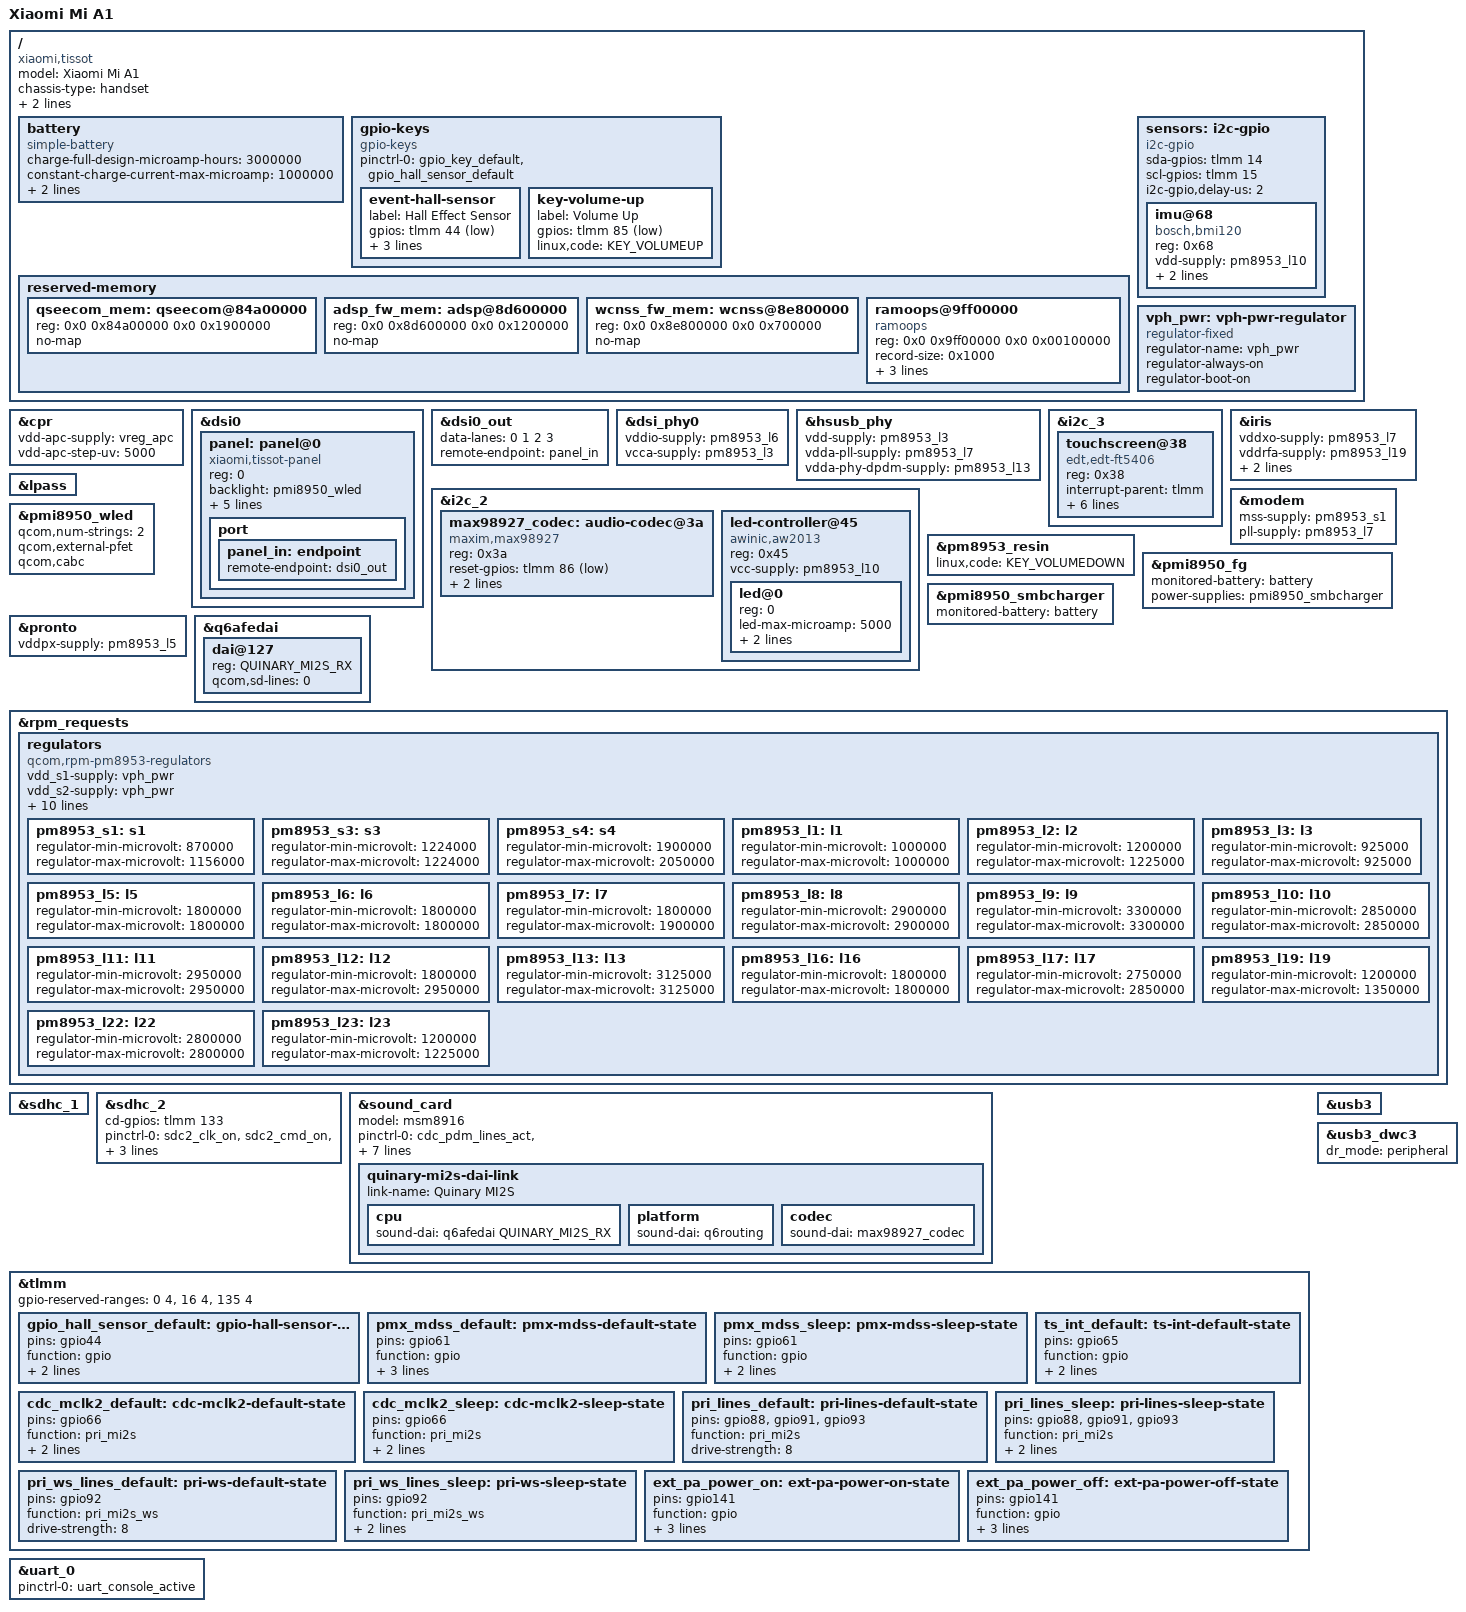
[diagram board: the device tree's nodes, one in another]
// SPDX-License-Identifier: BSD-3-Clause
/*
 * Copyright (c) 2022, Danila Tikhonov <JIaxyga@protonmail.com>
 * Copyright (c) 2022, Anton Bambura <jenneron@protonmail.com>
 */
/dts-v1/;

#include "msm8953.dtsi"
#include "pm8953.dtsi"
#include "pmi8950.dtsi"
#include <dt-bindings/leds/common.h>

/delete-node/ &adsp_fw_mem;
/delete-node/ &wcnss_fw_mem;

/ {
	model = "Xiaomi Mi A1";
	compatible = "xiaomi,tissot", "qcom,msm8953";
	chassis-type = "handset";
	qcom,msm-id = <293 0>;
	qcom,board-id = <0x1000b 0x00>;

	battery: battery {
		compatible = "simple-battery";
		charge-full-design-microamp-hours = <3000000>;
		constant-charge-current-max-microamp = <1000000>;
		voltage-min-design-microvolt = <3400000>;
		voltage-max-design-microvolt = <4400000>;
	};

	gpio-keys {
		compatible = "gpio-keys";

		pinctrl-names = "default";
		pinctrl-0 = <&gpio_key_default>, <&gpio_hall_sensor_default>;

		event-hall-sensor {
			label = "Hall Effect Sensor";
			gpios = <&tlmm 44 GPIO_ACTIVE_LOW>;
			linux,input-type = <EV_SW>;
			linux,code = <SW_LID>;
			linux,can-disable;
		};

		key-volume-up {
			label = "Volume Up";
			gpios = <&tlmm 85 GPIO_ACTIVE_LOW>;
			linux,code = <KEY_VOLUMEUP>;
		};
	};

	reserved-memory {
		/delete-node/memory@85b00000;
		qseecom_mem: qseecom@84a00000 {
			reg = <0x0 0x84a00000 0x0 0x1900000>;
			no-map;
		};

		adsp_fw_mem: adsp@8d600000 {
			reg = <0x0 0x8d600000 0x0 0x1200000>;
			no-map;
		};

		wcnss_fw_mem: wcnss@8e800000 {
			reg = <0x0 0x8e800000 0x0 0x700000>;
			no-map;
		};

		ramoops@9ff00000 {
			compatible = "ramoops";
			reg = <0x0 0x9ff00000 0x0 0x00100000>;
			record-size = <0x1000>;
			console-size = <0x80000>;
			ftrace-size = <0x1000>;
			pmsg-size = <0x8000>;
		};
	};

	sensors: i2c-gpio {
		compatible = "i2c-gpio";
		sda-gpios = <&tlmm 14 (GPIO_ACTIVE_HIGH|GPIO_OPEN_DRAIN)>;
		scl-gpios = <&tlmm 15 (GPIO_ACTIVE_HIGH|GPIO_OPEN_DRAIN)>;
		i2c-gpio,delay-us = <2>;        /* ~100 kHz */
		#address-cells = <1>;
		#size-cells = <0>;

		imu@68 {
			compatible = "bosch,bmi120";
			reg = <0x68>;

			vdd-supply = <&pm8953_l10>;
			vddio-supply = <&pm8953_l6>;

			mount-matrix = "0", "1", "0",
					"1", "0", "0",
					"0", "0", "1";
		};
	};

	vph_pwr: vph-pwr-regulator {
		compatible = "regulator-fixed";
		regulator-name = "vph_pwr";
		regulator-always-on;
		regulator-boot-on;
	};
};

&cpr {
	vdd-apc-supply = <&vreg_apc>;
	vdd-apc-step-uv = <5000>;
};

&dsi0 {
	panel: panel@0 {
		compatible = "xiaomi,tissot-panel";
		reg = <0>;

		backlight = <&pmi8950_wled>;

		reset-gpios = <&tlmm 61 GPIO_ACTIVE_LOW>;

		pinctrl-names = "default", "sleep";
		pinctrl-0 = <&pmx_mdss_default &mdss_te_default>;
		pinctrl-1 = <&pmx_mdss_sleep &mdss_te_default>;

		vsp-supply = <&lab_vreg>;
		vsn-supply = <&ibb_vreg>;

		port {
			panel_in: endpoint {
				remote-endpoint = <&dsi0_out>;
			};
		};
	};
};

&dsi0_out {
	data-lanes = <0 1 2 3>;
	remote-endpoint = <&panel_in>;
};

&dsi_phy0 {
	vddio-supply = <&pm8953_l6>;
	vcca-supply = <&pm8953_l3>;
};

&hsusb_phy {
	vdd-supply = <&pm8953_l3>;
	vdda-pll-supply = <&pm8953_l7>;
	vdda-phy-dpdm-supply = <&pm8953_l13>;

	status = "okay";
};

&i2c_2 {
	status = "okay";

	max98927_codec: audio-codec@3a {
		compatible = "maxim,max98927";
		reg = <0x3a>;

		reset-gpios = <&tlmm 86 GPIO_ACTIVE_LOW>;

		vmon-slot-no = <1>;
		imon-slot-no = <1>;

		#sound-dai-cells = <1>;
	};

	led-controller@45 {
		compatible = "awinic,aw2013";
		reg = <0x45>;

		vcc-supply = <&pm8953_l10>;

		#address-cells = <1>;
		#size-cells = <0>;

		led@0 {
			reg = <0>;
			led-max-microamp = <5000>;
			function = LED_FUNCTION_INDICATOR;
			color = <LED_COLOR_ID_WHITE>;
		};
	};
};

&i2c_3 {
	status = "okay";

	touchscreen@38 {
		compatible = "edt,edt-ft5406";
		reg = <0x38>;

		interrupt-parent = <&tlmm>;
		interrupts = <65 IRQ_TYPE_EDGE_FALLING>;

		pinctrl-names = "default";
		pinctrl-0 = <&ts_int_default>;

		reset-gpios = <&tlmm 64 GPIO_ACTIVE_LOW>;

		vcc-supply = <&pm8953_l10>;

		touchscreen-size-x = <1080>;
		touchscreen-size-y = <1920>;
	};
};

&iris {
	vddxo-supply = <&pm8953_l7>;
	vddrfa-supply = <&pm8953_l19>;
	vddpa-supply = <&pm8953_l9>;
	vdddig-supply = <&pm8953_l5>;

	status = "okay";
};

&lpass {
	status = "okay";
};

&modem {
	status = "okay";

	mss-supply = <&pm8953_s1>;
	pll-supply = <&pm8953_l7>;
};

&pm8953_resin {
	status = "okay";
	linux,code = <KEY_VOLUMEDOWN>;
};

&pmi8950_fg {
	monitored-battery = <&battery>;
	power-supplies = <&pmi8950_smbcharger>;
	status = "okay";
};

&pmi8950_smbcharger {
	monitored-battery = <&battery>;
	status = "okay";
};

&pmi8950_wled {
	status = "okay";

	qcom,num-strings = <2>;
	qcom,external-pfet;
	qcom,cabc;
};

&pronto {
	status = "okay";
	vddpx-supply = <&pm8953_l5>;
};

&q6afedai {
	dai@127 {
		reg = <QUINARY_MI2S_RX>;
		qcom,sd-lines = <0>;
	};
};

&rpm_requests {
	regulators {
		compatible = "qcom,rpm-pm8953-regulators";

		vdd_s1-supply = <&vph_pwr>;
		vdd_s2-supply = <&vph_pwr>;
		vdd_s3-supply = <&vph_pwr>;
		vdd_s4-supply = <&vph_pwr>;
		vdd_s5-supply = <&vph_pwr>;
		vdd_s6-supply = <&vph_pwr>;
		vdd_s7-supply = <&vph_pwr>;
		vdd_l1-supply = <&pm8953_s3>;
		vdd_l2_l3-supply = <&pm8953_s3>;
		vdd_l4_l5_l6_l7_l16_l19-supply = <&pm8953_s4>;
		vdd_l8_l11_l12_l13_l14_l15-supply = <&vph_pwr>;
		vdd_l9_l10_l17_l18_l22-supply = <&vph_pwr>;

		pm8953_s1: s1 {
			regulator-min-microvolt = <870000>;
			regulator-max-microvolt = <1156000>;
		};

		pm8953_s3: s3 {
			regulator-min-microvolt = <1224000>;
			regulator-max-microvolt = <1224000>;
		};

		pm8953_s4: s4 {
			regulator-min-microvolt = <1900000>;
			regulator-max-microvolt = <2050000>;
		};

		pm8953_l1: l1 {
			regulator-min-microvolt = <1000000>;
			regulator-max-microvolt = <1000000>;
		};

		pm8953_l2: l2 {
			regulator-min-microvolt = <1200000>;
			regulator-max-microvolt = <1225000>;
		};

		pm8953_l3: l3 {
			regulator-min-microvolt = <925000>;
			regulator-max-microvolt = <925000>;
		};

		pm8953_l5: l5 {
			regulator-min-microvolt = <1800000>;
			regulator-max-microvolt = <1800000>;
		};

		pm8953_l6: l6 {
			regulator-min-microvolt = <1800000>;
			regulator-max-microvolt = <1800000>;
		};

		pm8953_l7: l7 {
			regulator-min-microvolt = <1800000>;
			regulator-max-microvolt = <1900000>;
		};

		pm8953_l8: l8 {
			regulator-min-microvolt = <2900000>;
			regulator-max-microvolt = <2900000>;
		};

		pm8953_l9: l9 {
			regulator-min-microvolt = <3300000>;
			regulator-max-microvolt = <3300000>;
		};

		pm8953_l10:l10 {
			regulator-min-microvolt = <2850000>;
			regulator-max-microvolt = <2850000>;
		};

		pm8953_l11: l11 {
			regulator-min-microvolt = <2950000>;
			regulator-max-microvolt = <2950000>;
		};

		pm8953_l12: l12 {
			regulator-min-microvolt = <1800000>;
			regulator-max-microvolt = <2950000>;
		};

		pm8953_l13: l13 {
			regulator-min-microvolt = <3125000>;
			regulator-max-microvolt = <3125000>;
		};

		pm8953_l16: l16 {
			regulator-min-microvolt = <1800000>;
			regulator-max-microvolt = <1800000>;
		};

		pm8953_l17: l17 {
			regulator-min-microvolt = <2750000>;
			regulator-max-microvolt = <2850000>;
		};

		pm8953_l19: l19 {
			regulator-min-microvolt = <1200000>;
			regulator-max-microvolt = <1350000>;
		};

		pm8953_l22: l22 {
			regulator-min-microvolt = <2800000>;
			regulator-max-microvolt = <2800000>;
		};

		pm8953_l23: l23 {
			regulator-min-microvolt = <1200000>;
			regulator-max-microvolt = <1225000>;
		};
	};
};

&sdhc_1 {
	status = "okay";
};

&sdhc_2 {
	cd-gpios = <&tlmm 133 GPIO_ACTIVE_HIGH>;

	pinctrl-names = "default", "sleep";
	pinctrl-0 = <&sdc2_clk_on &sdc2_cmd_on &sdc2_data_on &sdc2_cd_on>;
	pinctrl-1 = <&sdc2_clk_off &sdc2_cmd_off &sdc2_data_off &sdc2_cd_off>;

	status = "okay";
};

&sound_card {
	status = "okay";

	model = "msm8916";

	pinctrl-names = "default", "sleep";
	pinctrl-0 = <&cdc_pdm_lines_act &cdc_pdm_lines_2_act &cdc_pdm_comp_lines_act &pri_lines_default &pri_ws_lines_default &ext_pa_power_on>;
	pinctrl-1 = <&cdc_pdm_lines_sus &cdc_pdm_lines_2_sus &cdc_pdm_comp_lines_sus &pri_lines_sleep &pri_ws_lines_sleep &ext_pa_power_off>;

	quinary-mi2s-dai-link {
		link-name = "Quinary MI2S";
		cpu {
			sound-dai = <&q6afedai QUINARY_MI2S_RX>;
		};

		platform {
			sound-dai = <&q6routing>;
		};

		codec {
			sound-dai = <&max98927_codec>;
		};
	};
};

&tlmm {
	gpio-reserved-ranges = <0 4>, <16 4>, <135 4>;

	gpio_hall_sensor_default: gpio-hall-sensor-state {
		pins = "gpio44";
		function = "gpio";
		drive-strength = <2>;
		bias-pull-up;
	};

	pmx_mdss_default: pmx-mdss-default-state {
		pins = "gpio61";
		function = "gpio";
		drive-strength = <8>;
		bias-disable = <0>;
		output-high;
	};

	pmx_mdss_sleep: pmx-mdss-sleep-state {
		pins = "gpio61";
		function = "gpio";
		drive-strength = <2>;
		bias-pull-down;
	};

	ts_int_default: ts-int-default-state {
		pins = "gpio65";
		function = "gpio";
		drive-strength = <2>;
		bias-pull-up;
	};

	cdc_mclk2_default: cdc-mclk2-default-state {
		pins = "gpio66";
		function = "pri_mi2s";
		drive-strength = <8>;
		bias-disable;
	};

	cdc_mclk2_sleep: cdc-mclk2-sleep-state {
		pins = "gpio66";
		function = "pri_mi2s";
		drive-strength = <2>;
		bias-pull-down;
	};

	pri_lines_default: pri-lines-default-state {
		pins = "gpio88", "gpio91", "gpio93";
		function = "pri_mi2s";
		drive-strength = <8>;
	};

	pri_lines_sleep: pri-lines-sleep-state {
		pins = "gpio88", "gpio91", "gpio93";
		function = "pri_mi2s";
		drive-strength = <2>;
		bias-pull-down;
	};

	pri_ws_lines_default: pri-ws-default-state {
		pins = "gpio92";
		function = "pri_mi2s_ws";
		drive-strength = <8>;
	};

	pri_ws_lines_sleep: pri-ws-sleep-state {
		pins = "gpio92";
		function = "pri_mi2s_ws";
		drive-strength = <2>;
		bias-pull-down;
	};

	ext_pa_power_on: ext-pa-power-on-state {
		pins = "gpio141";
		function = "gpio";
		drive-strength = <16>;
		bias-disable;
		output-high;
	};

	ext_pa_power_off: ext-pa-power-off-state {
		pins = "gpio141";
		function = "gpio";
		drive-strength = <16>;
		bias-disable;
		output-low;
	};
};

&uart_0 {
	pinctrl-names = "default";
	pinctrl-0 = <&uart_console_active>;

	status = "okay";
};

&usb3 {
	status = "okay";
};

&usb3_dwc3 {
	dr_mode = "peripheral";
};
